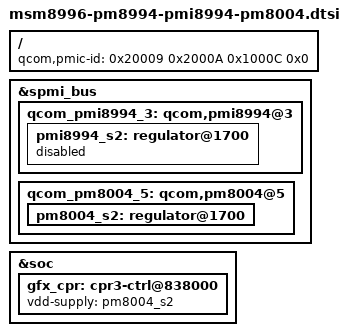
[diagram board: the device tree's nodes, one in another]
/* Copyright (c) 2015, 2019, The Linux Foundation. All rights reserved.
 *
 * This program is free software; you can redistribute it and/or modify
 * it under the terms of the GNU General Public License version 2 and
 * only version 2 as published by the Free Software Foundation.
 *
 * This program is distributed in the hope that it will be useful,
 * but WITHOUT ANY WARRANTY; without even the implied warranty of
 * MERCHANTABILITY or FITNESS FOR A PARTICULAR PURPOSE.  See the
 * GNU General Public License for more details.
 */

/*
 * As a general rule, only chipset-specific property overrides should be placed
 * inside this file.
 */

#include "msm-pm8004.dtsi"

/ {
	qcom,pmic-id = <0x20009 0x2000A 0x1000C 0x0>;
};

/*
 * Override PMI8994 resources with proper PM8004 resources for MSM8996 with
 * PM8004.
 */

&spmi_bus {
	qcom_pmi8994_3: qcom,pmi8994@3 {
		pmi8994_s2: regulator@1700 {
			status = "disabled";
		};
	};
};

&spmi_bus {
	qcom_pm8004_5: qcom,pm8004@5 {
		pm8004_s2: regulator@1700 {
			status = "ok";
		};
	};
};

&soc {
	gfx_cpr: cpr3-ctrl@838000 {
		vdd-supply = <&pm8004_s2>;
	};
};
